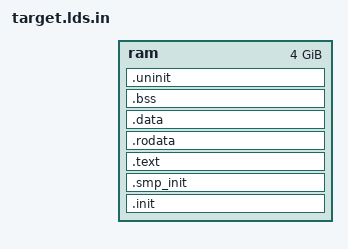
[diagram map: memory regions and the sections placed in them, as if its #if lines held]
#include "arch/memory.h"
#include "page.h"

#ifdef CONFIG_REMOVE_INIT_SECTIONS
#define	TEXT_ALIGN	ALIGN(PAGE_SIZE)
#else
#define	TEXT_ALIGN	
#endif

ENTRY(_os_startup)

MEMORY {
	ram		: ORIGIN = VIRT_ADDR + TEXT_OFFSET, LENGTH = 0xFFFFFFFF
}

SECTIONS
{
	.init : {
			*(.startup.text)
			*(.init.text)

#ifdef	CONFIG_INITCALL
		PROVIDE(__INITCALL_LIST__ = .);
			KEEP(*(SORT(.initcall*)))
			LONG(0);
#endif
	} > ram

#ifdef CONFIG_SMP
	.smp_init : WORD_ALIGN {
		PROVIDE(__SMP_INITCALL_LIST__ = .);
			KEEP(*(SORT(.smp_initcall*)))
			LONG(0);
	} > ram
#endif

	.text TEXT_ALIGN : {
			*(.text*)
	} > ram

	.rodata : {
			*(.rodata*)
	} > ram

	.data : {
			*(.data*)
	} > ram

	.bss : {
		PROVIDE(__bss_start = .);
			*(.bss*)
			*(COMMON)
		PROVIDE(__bss_end = .);
	} > ram

	.uninit (NOLOAD) TEXT_ALIGN : {
			*(SORT_BY_ALIGNMENT(.uninit*))
	} > ram

	. = ALIGN(PAGE_SIZE);
	PROVIDE(pagemap = .);


    /DISCARD/ :
	{
		*(.MIPS.abiflags)
		*(.rel.dyn)
	}
}
